# WS53 register map
File version: 0.1.0-experimental
Registers are 32-bit, read-write, no defined reset value unless marked. A register's access mark holds for its fields unless they carry their own. Offsets are from the block's base; [hi:lo] are bit positions; {n}, {i} and the like mark numbered series; 'fields as' and 'values as' point back to an identical list.

## SYSTEM_MEMORY
Base 0x57030000
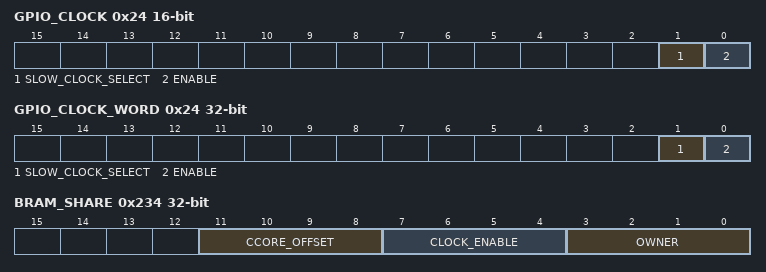
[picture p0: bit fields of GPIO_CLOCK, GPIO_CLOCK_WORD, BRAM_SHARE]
0x24 GPIO_CLOCK 16-bit
  [1] SLOW_CLOCK_SELECT — SDK clock recovery writes 3 for GPIO 32K and 1 for PLL/fast source. Frequency, APB versus interrupt-clock coverage, and low-power behavior remain silicon-unqualified
  [0] ENABLE — SDK AGPIO clock enable; application initialization sets bit0 before GPIO1 use. Preserve the handed-off source and other clock bits. Shared with sleep/wakeup code; no automatic disable or exclusive ownership is implied
0x24 GPIO_CLOCK_WORD (alternate view of GPIO_CLOCK) — 32-bit little-endian access view of GPIO_CLOCK; same low-half fields, upper bits unmodeled; preserve them on RMW. SDK 163d9150 ws53_application/main.c dev_work_clock_init unconditionally uses reg16_setbit(0x57030024,0), including BOARD_ASIC. clock_recover.c and pm_porting.c also use word writes 1/3/0. Shared AGPIO/ULP clock; reset value and silicon timing are unknown. SPI23 Flash failure reaches the GPIO1 access stage while factory-initialized RAM works; this is not yet controlled gate-causality proof
  fields as GPIO_CLOCK
0x234 BRAM_SHARE
  [11:8] CCORE_OFFSET — Ccore shared RAM address offset
  [7:4] CLOCK_ENABLE — One clock gate per shared RAM pair
  [3:0] OWNER — RAM6/7,8/9,10/11,12/13: 0 acore, 1 ccore
0x238 DTCM_SHARE
  [5:0] DTCM_SELECT — RAM0..5: 0 ITCM, 1 DTCM
0x604 PLATFORM_ENABLE
  [8:6] MCU_MODE — MCU mode encoded bits: mode1=0, mode2=1, mode3=2, mode4=4
0x96C CCORE_RESET_STATUS ro — Control-core reset observation; no reset command is exposed by this view
  [2:0] RELEASED_DOMAINS — Known domain-release encoding: 0 all held, 3 logic/clock released, 7 CPU also released; other encodings unqualified
0x96C CCORE_LOGIC_CLOCK_RELEASE_COMMAND wo (alternate view of CCORE_RESET_STATUS) — Restricted full-word logic/clock release command, retaining control CPU reset
  [31:0] LOGIC_CLOCK_RELEASE range 3..3 — Write exactly 3 after exclusive domain handoff from state0, wait at least SDK 5us and verify status3; CPU bit2 stays zero. This is a shared domain, not just TSENSOR. Reset state and other command values are not modeled; SVD constraints do not guard unsafe raw PAC writes

## PINMUX_AON
Base 0x57036000
{0x0+4i} AGPIO{i}_SEL (i=1..5)
  [2:0] MODE — Pin-specific mux selection; legal functions depend on the pad
0x18 AGPIO10_SEL
  fields as AGPIO1_SEL
0x1C AGPIO11_SEL
  fields as AGPIO1_SEL
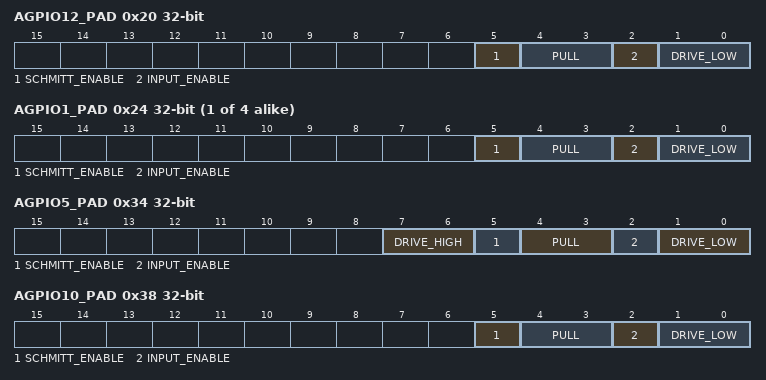
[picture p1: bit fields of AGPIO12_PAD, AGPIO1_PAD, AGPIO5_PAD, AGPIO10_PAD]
0x20 AGPIO12_PAD
  [5] SCHMITT_ENABLE
  [4:3] PULL — 0 none, 1 pull-up, 2 pull-down; 3 is not a supported SDK setting
  [2] INPUT_ENABLE
  [1:0] DRIVE_LOW
{0x20+4i} AGPIO{i}_PAD (i=1..4)
  fields as AGPIO12_PAD
0x34 AGPIO5_PAD
  [7:6] DRIVE_HIGH — Drive code bits 3:2, present only on MGPIO0/2/3/4 and AGPIO5/6
  [5] SCHMITT_ENABLE
  [4:3] PULL — 0 none, 1 pull-up, 2 pull-down; 3 is not a supported SDK setting
  [2] INPUT_ENABLE
  [1:0] DRIVE_LOW
0x38 AGPIO10_PAD
  fields as AGPIO12_PAD
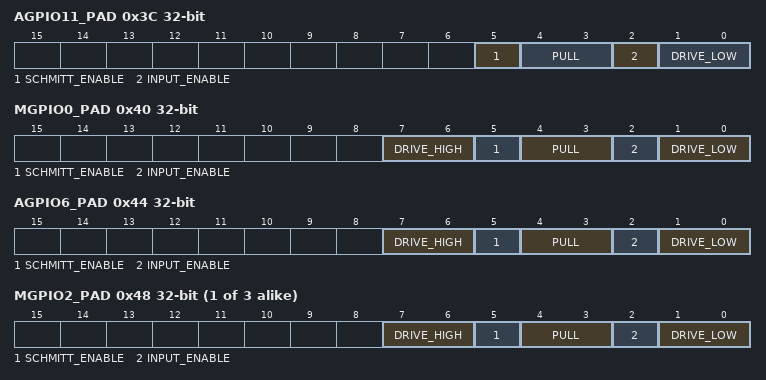
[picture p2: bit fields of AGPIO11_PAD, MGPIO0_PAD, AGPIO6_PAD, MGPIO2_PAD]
0x3C AGPIO11_PAD
  fields as AGPIO12_PAD
0x40 MGPIO0_PAD
  fields as AGPIO5_PAD
0x44 AGPIO6_PAD
  fields as AGPIO5_PAD
{0x40+4i} MGPIO{i}_PAD (i=2..4)
  fields as AGPIO5_PAD
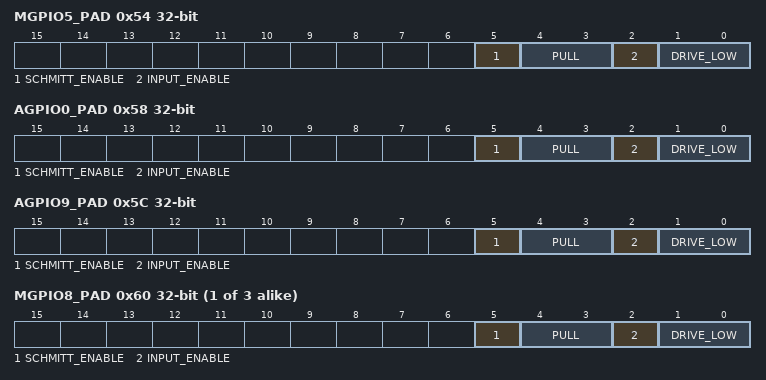
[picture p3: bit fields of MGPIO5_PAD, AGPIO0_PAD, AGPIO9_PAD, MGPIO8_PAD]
0x54 MGPIO5_PAD
  fields as AGPIO12_PAD
0x58 AGPIO0_PAD
  fields as AGPIO12_PAD
0x5C AGPIO9_PAD
  fields as AGPIO12_PAD
{0x40+4i} MGPIO{i}_PAD (i=8..10)
  fields as AGPIO12_PAD
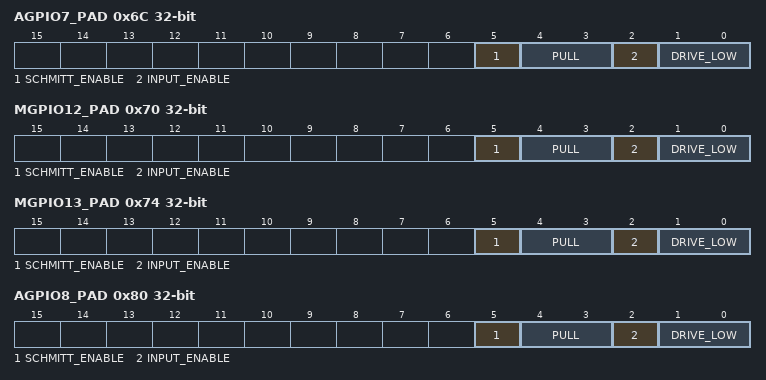
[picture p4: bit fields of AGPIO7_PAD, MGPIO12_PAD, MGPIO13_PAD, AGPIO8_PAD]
0x6C AGPIO7_PAD
  fields as AGPIO12_PAD
0x70 MGPIO12_PAD
  fields as AGPIO12_PAD
0x74 MGPIO13_PAD
  fields as AGPIO12_PAD
0x80 AGPIO8_PAD
  fields as AGPIO12_PAD
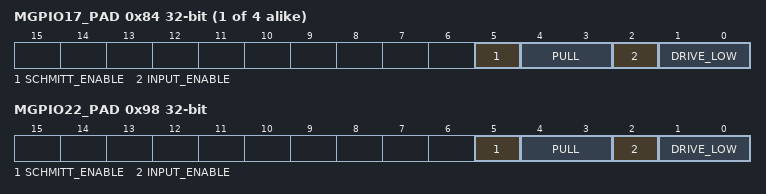
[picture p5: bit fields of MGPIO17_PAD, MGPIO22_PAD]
{0x40+4i} MGPIO{i}_PAD (i=17..20)
  fields as AGPIO12_PAD
0x98 MGPIO22_PAD
  fields as AGPIO12_PAD
0xB8 AGPIO6_SEL
  fields as AGPIO1_SEL
0xBC AGPIO0_SEL
  fields as AGPIO1_SEL
0xC0 AGPIO9_SEL
  fields as AGPIO1_SEL
0xC4 AGPIO7_SEL
  fields as AGPIO1_SEL
0xC8 AGPIO8_SEL
  fields as AGPIO1_SEL

## PINMUX_TZPC
Base 0x5703A000
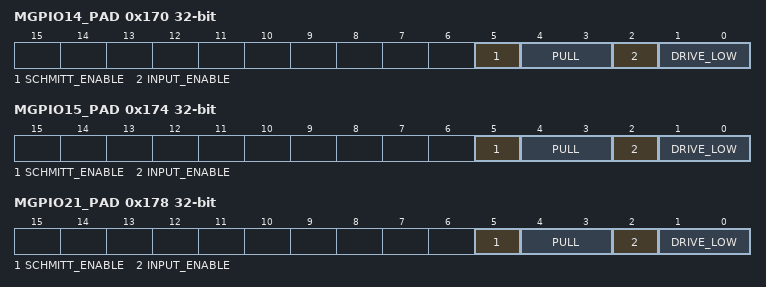
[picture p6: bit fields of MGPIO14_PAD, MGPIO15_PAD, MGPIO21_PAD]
0x170 MGPIO14_PAD
  [5] SCHMITT_ENABLE
  [4:3] PULL — 0 none, 1 pull-up, 2 pull-down; 3 is not a supported SDK setting
  [2] INPUT_ENABLE
  [1:0] DRIVE_LOW
0x174 MGPIO15_PAD
  fields as MGPIO14_PAD
0x178 MGPIO21_PAD
  fields as MGPIO14_PAD

## TSENSOR
Base 0x59006300
0x00 START wo — Command view: SDK writes 1 to start. A-board repeated START1 clears READY without clearing previous CODE; stop and command self-clear behavior unspecified
  [31:0] VALUE
0x04 CONTROL — Opaque configuration: SDK writes 3 for 16-point average cyclic reports, reads zero as uninitialized
  [31:0] VALUE
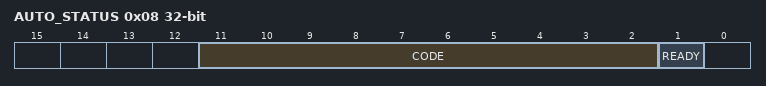
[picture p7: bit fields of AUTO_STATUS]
0x08 AUTO_STATUS ro — Polling status subset. Bit 0 named auto_clr has no evidenced write/clear semantics and is omitted
  [11:2] CODE — Ten-bit result valid only with READY=1. A-board START1 observation retains the prior code while READY=0; that stale field is not a completed sample
  [1] READY
0x10 SAMPLE_TIME wo — Opaque write view: SDK writes 2 for 0.256 ms per sample; readback unspecified
  [31:0] VALUE
0x30 AUTO_REFRESH_PERIOD wo — Opaque write view: SDK writes 160 cycles of the 32 kHz source (5 ms); implemented width unknown
  [31:0] VALUE
0x34 AUTO_REFRESH_CONFIG wo — Opaque write view: SDK writes 0 to disable auto-refresh reporting; readback unspecified
  [31:0] VALUE
